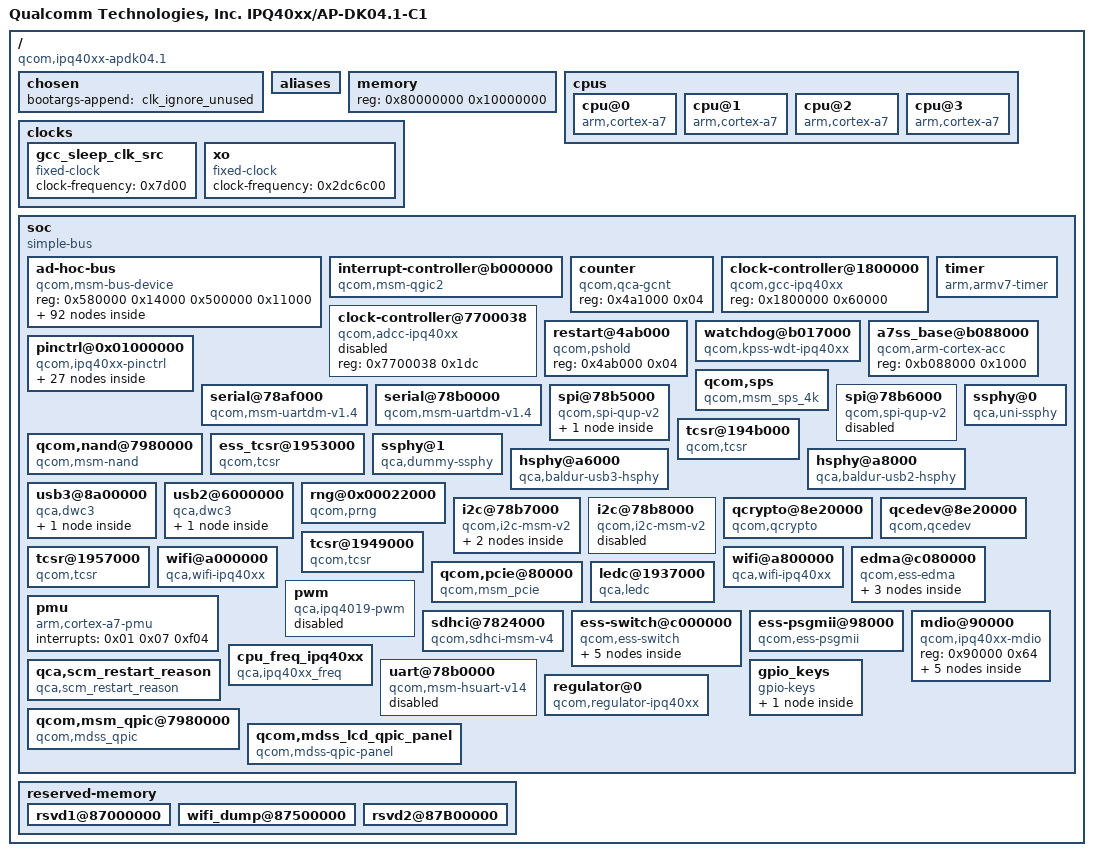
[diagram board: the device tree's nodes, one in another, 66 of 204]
/dts-v1/;

/ {
	#address-cells = <0x01>;
	#size-cells = <0x01>;
	model = "Qualcomm Technologies, Inc. IPQ40xx/AP-DK04.1-C1";
	compatible = "qcom,ipq40xx-apdk04.1\0qcom,ipq40xx";
	interrupt-parent = <0x01>;

	chosen {
		bootargs-append = " clk_ignore_unused";
	};

	aliases {
		spi0 = "/soc/spi@78b5000";
		spi1 = "/soc/spi@78b6000";
		i2c0 = "/soc/i2c@78b7000";
		i2c1 = "/soc/i2c@78b8000";
		ethernet0 = "/soc/edma/gmac0";
		ethernet1 = "/soc/edma/gmac1";
		ethernet2 = "/soc/edma/gmac2";
	};

	memory {
		device_type = "memory";
		reg = <0x80000000 0x10000000>;
	};

	cpus {
		#address-cells = <0x01>;
		#size-cells = <0x00>;

		cpu@0 {
			device_type = "cpu";
			compatible = "arm,cortex-a7";
			enable-method = "qcom,arm-cortex-acc";
			reg = <0x00>;
			clocks = <0x02 0x09>;
			clock-frequency = <0x00>;
		};

		cpu@1 {
			device_type = "cpu";
			compatible = "arm,cortex-a7";
			enable-method = "qcom,arm-cortex-acc";
			reg = <0x01>;
			clocks = <0x02 0x09>;
			clock-frequency = <0x00>;
		};

		cpu@2 {
			device_type = "cpu";
			compatible = "arm,cortex-a7";
			enable-method = "qcom,arm-cortex-acc";
			reg = <0x02>;
			clocks = <0x02 0x09>;
			clock-frequency = <0x00>;
		};

		cpu@3 {
			device_type = "cpu";
			compatible = "arm,cortex-a7";
			enable-method = "qcom,arm-cortex-acc";
			reg = <0x03>;
			clocks = <0x02 0x09>;
			clock-frequency = <0x00>;
		};
	};

	clocks {

		gcc_sleep_clk_src {
			compatible = "fixed-clock";
			clock-frequency = <0x7d00>;
			#clock-cells = <0x00>;
			linux,phandle = <0x47>;
			phandle = <0x47>;
		};

		xo {
			compatible = "fixed-clock";
			clock-frequency = <0x2dc6c00>;
			#clock-cells = <0x00>;
		};
	};

	soc {
		#address-cells = <0x01>;
		#size-cells = <0x01>;
		ranges;
		compatible = "simple-bus";

		ad-hoc-bus {
			compatible = "qcom,msm-bus-device";
			reg = <0x580000 0x14000 0x500000 0x11000>;
			reg-names = "snoc-base\0pcnoc-base";

			fab-pcnoc {
				cell-id = <0x1000>;
				label = "fab-pcnoc";
				qcom,fab-dev;
				qcom,base-name = "pcnoc-base";
				qcom,bypass-qos-prg;
				qcom,bus-type = <0x01>;
				qcom,qos-off = <0x1000>;
				qcom,base-offset = <0x00>;
				clocks;
				linux,phandle = <0x04>;
				phandle = <0x04>;
			};

			fab-snoc {
				cell-id = <0x400>;
				label = "fab-snoc";
				qcom,fab-dev;
				qcom,base-name = "snoc-base";
				qcom,bypass-qos-prg;
				qcom,bus-type = <0x01>;
				qcom,qos-off = <0x80>;
				qcom,base-offset = <0x00>;
				clocks;
				linux,phandle = <0x31>;
				phandle = <0x31>;
			};

			mas-blsp-bam {
				cell-id = <0x6d>;
				label = "mas-blsp-bam";
				qcom,buswidth = <0x04>;
				qcom,ap-owned;
				qcom,connections = <0x03>;
				qcom,bus-dev = <0x04>;
				qcom,mas-rpm-id = <0x82>;
				qcom,blacklist = <0x05 0x06 0x07 0x08 0x09 0x0a 0x0b 0x0c 0x0d 0x0e 0x0f 0x10 0x11 0x12 0x13 0x14 0x15 0x16 0x17 0x18 0x19 0x1a 0x1b 0x1c 0x1d 0x1e 0x1f 0x20 0x21 0x22 0x23 0x24 0x25 0x26 0x27 0x28 0x29 0x2a>;
			};

			mas-usb2-bam {
				cell-id = <0x6e>;
				label = "mas-usb2-bam";
				qcom,buswidth = <0x08>;
				qcom,ap-owned;
				qcom,qport = <0x0f>;
				qcom,qos-mode = "fixed";
				qcom,connections = <0x2b>;
				qcom,prio1 = <0x01>;
				qcom,prio0 = <0x01>;
				qcom,bus-dev = <0x04>;
				qcom,mas-rpm-id = <0x83>;
				qcom,blacklist = <0x05 0x06 0x07 0x08 0x09 0x0a 0x0b 0x0c 0x0d 0x0e 0x0f 0x10 0x11 0x12 0x13 0x14 0x15 0x16 0x17 0x18 0x19 0x1a 0x1b 0x1c 0x1d 0x1e 0x1f 0x20 0x21 0x22 0x23 0x24 0x25 0x26 0x27 0x28 0x29 0x2a>;
			};

			mas-adss-dma0 {
				cell-id = <0x6f>;
				label = "mas-adss-dma0";
				qcom,buswidth = <0x04>;
				qcom,ap-owned;
				qcom,connections = <0x2c>;
				qcom,bus-dev = <0x04>;
				qcom,mas-rpm-id = <0x84>;
				qcom,blacklist = <0x05 0x06 0x07 0x08 0x09 0x0a 0x0b 0x0c 0x0d 0x0e 0x0f 0x10 0x11 0x12 0x13 0x14 0x15 0x16 0x17 0x18 0x19 0x1a 0x1b 0x1c 0x1d 0x1e 0x1f 0x20 0x21 0x22 0x23 0x24 0x25 0x26 0x27 0x28 0x29 0x2a>;
			};

			mas-adss-dma1 {
				cell-id = <0x70>;
				label = "mas-adss-dma1";
				qcom,buswidth = <0x04>;
				qcom,ap-owned;
				qcom,connections = <0x2c>;
				qcom,bus-dev = <0x04>;
				qcom,mas-rpm-id = <0x85>;
				qcom,blacklist = <0x05 0x06 0x07 0x08 0x09 0x0a 0x0b 0x0c 0x0d 0x0e 0x0f 0x10 0x11 0x12 0x13 0x14 0x15 0x16 0x17 0x18 0x19 0x1a 0x1b 0x1c 0x1d 0x1e 0x1f 0x20 0x21 0x22 0x23 0x24 0x25 0x26 0x27 0x28 0x29 0x2a>;
			};

			mas-adss-dma2 {
				cell-id = <0x71>;
				label = "mas-adss-dma2";
				qcom,buswidth = <0x04>;
				qcom,ap-owned;
				qcom,connections = <0x2c>;
				qcom,bus-dev = <0x04>;
				qcom,mas-rpm-id = <0x86>;
				qcom,blacklist = <0x05 0x06 0x07 0x08 0x09 0x0a 0x0b 0x0c 0x0d 0x0e 0x0f 0x10 0x11 0x12 0x13 0x14 0x15 0x16 0x17 0x18 0x19 0x1a 0x1b 0x1c 0x1d 0x1e 0x1f 0x20 0x21 0x22 0x23 0x24 0x25 0x26 0x27 0x28 0x29 0x2a>;
			};

			mas-adss-dma3 {
				cell-id = <0x72>;
				label = "mas-adss-dma3";
				qcom,buswidth = <0x04>;
				qcom,ap-owned;
				qcom,connections = <0x2c>;
				qcom,bus-dev = <0x04>;
				qcom,mas-rpm-id = <0x87>;
				qcom,blacklist = <0x05 0x06 0x07 0x08 0x09 0x0a 0x0b 0x0c 0x0d 0x0e 0x0f 0x10 0x11 0x12 0x13 0x14 0x15 0x16 0x17 0x18 0x19 0x1a 0x1b 0x1c 0x1d 0x1e 0x1f 0x20 0x21 0x22 0x23 0x24 0x25 0x26 0x27 0x28 0x29 0x2a>;
			};

			mas-qpic-bam {
				cell-id = <0x73>;
				label = "mas-qpic-bam";
				qcom,buswidth = <0x04>;
				qcom,ap-owned;
				qcom,connections = <0x03>;
				qcom,bus-dev = <0x04>;
				qcom,mas-rpm-id = <0x88>;
				qcom,blacklist = <0x05 0x06 0x07 0x08 0x09 0x0a 0x0b 0x0c 0x0d 0x0e 0x0f 0x10 0x11 0x12 0x13 0x14 0x15 0x16 0x17 0x18 0x19 0x1a 0x1b 0x1c 0x1d 0x1e 0x1f 0x20 0x21 0x22 0x23 0x24 0x25 0x26 0x27 0x28 0x29 0x2a>;
			};

			mas-spdm {
				cell-id = <0x24>;
				label = "mas-spdm";
				qcom,buswidth = <0x04>;
				qcom,ap-owned;
				qcom,connections = <0x03>;
				qcom,bus-dev = <0x04>;
				qcom,mas-rpm-id = <0x32>;
				qcom,blacklist = <0x05 0x06 0x07 0x08 0x09 0x0a 0x0b 0x0c 0x0d 0x0e 0x0f 0x10 0x11 0x12 0x13 0x14 0x15 0x16 0x17 0x18 0x19 0x1a 0x1b 0x1c 0x1d 0x1e 0x1f 0x20 0x21 0x22 0x23 0x24 0x25 0x26 0x27 0x28 0x29 0x2a>;
			};

			mas-pcnoc-cfg {
				cell-id = <0x58>;
				label = "mas-pcnoc-cfg";
				qcom,buswidth = <0x04>;
				qcom,ap-owned;
				qcom,connections = <0x26>;
				qcom,bus-dev = <0x04>;
				qcom,mas-rpm-id = <0x54>;
			};

			mas-tic {
				cell-id = <0x4d>;
				label = "mas-tic";
				qcom,buswidth = <0x04>;
				qcom,ap-owned;
				qcom,connections = <0x2d 0x2b>;
				qcom,bus-dev = <0x04>;
				qcom,mas-rpm-id = <0x33>;
			};

			mas-sdcc-bam {
				cell-id = <0x74>;
				label = "mas-sdcc-bam";
				qcom,buswidth = <0x08>;
				qcom,ap-owned;
				qcom,qport = <0x0e>;
				qcom,qos-mode = "fixed";
				qcom,connections = <0x2b>;
				qcom,prio1 = <0x00>;
				qcom,prio0 = <0x00>;
				qcom,bus-dev = <0x04>;
				qcom,mas-rpm-id = <0x89>;
				qcom,blacklist = <0x05 0x06 0x07 0x08 0x09 0x0a 0x0b 0x0c 0x0d 0x0e 0x0f 0x10 0x11 0x12 0x13 0x14 0x15 0x16 0x17 0x18 0x19 0x1a 0x1b 0x1c 0x1d 0x1e 0x1f 0x20 0x21 0x22 0x23 0x24 0x25 0x26 0x27 0x28 0x29 0x2a>;
			};

			mas-snoc-pcnoc {
				cell-id = <0x2739>;
				label = "mas-snoc-pcnoc";
				qcom,buswidth = <0x04>;
				qcom,ap-owned;
				qcom,qport = <0x10>;
				qcom,qos-mode = "fixed";
				qcom,connections = <0x2d>;
				qcom,prio1 = <0x00>;
				qcom,prio0 = <0x00>;
				qcom,bus-dev = <0x04>;
				qcom,mas-rpm-id = <0x4d>;
			};

			mas-qdss-dap {
				cell-id = <0x4c>;
				label = "mas-qdss-dap";
				qcom,buswidth = <0x04>;
				qcom,ap-owned;
				qcom,connections = <0x2d 0x2b>;
				qcom,bus-dev = <0x04>;
				qcom,mas-rpm-id = <0x31>;
			};

			mas-ddrc-snoc {
				cell-id = <0x75>;
				label = "mas-ddrc-snoc";
				qcom,buswidth = <0x10>;
				qcom,ap-owned;
				qcom,connections = <0x2e 0x2f 0x30>;
				qcom,bus-dev = <0x31>;
				qcom,mas-rpm-id = <0x8a>;
				qcom,blacklist = <0x32 0x33>;
			};

			mas-wss-0 {
				cell-id = <0x76>;
				label = "mas-wss-0";
				qcom,buswidth = <0x04>;
				qcom,ap-owned;
				qcom,qport = <0x1a>;
				qcom,qos-mode = "fixed";
				qcom,connections = <0x2e 0x32>;
				qcom,prio1 = <0x00>;
				qcom,prio0 = <0x00>;
				qcom,bus-dev = <0x31>;
				qcom,mas-rpm-id = <0x8b>;
				qcom,blacklist = <0x34 0x35 0x30 0x36 0x37 0x38 0x33>;
			};

			mas-wss-1 {
				cell-id = <0x77>;
				label = "mas-wss-1";
				qcom,buswidth = <0x04>;
				qcom,ap-owned;
				qcom,qport = <0x1b>;
				qcom,qos-mode = "fixed";
				qcom,connections = <0x2e 0x32>;
				qcom,prio1 = <0x00>;
				qcom,prio0 = <0x00>;
				qcom,bus-dev = <0x31>;
				qcom,mas-rpm-id = <0x8c>;
				qcom,blacklist = <0x34 0x35 0x30 0x36 0x37 0x38 0x33>;
			};

			mas-crypto {
				cell-id = <0x2f>;
				label = "mas-crypto";
				qcom,buswidth = <0x08>;
				qcom,ap-owned;
				qcom,qport = <0x05>;
				qcom,qos-mode = "fixed";
				qcom,connections = <0x2e 0x2f 0x32>;
				qcom,prio1 = <0x00>;
				qcom,prio0 = <0x00>;
				qcom,bus-dev = <0x31>;
				qcom,mas-rpm-id = <0x17>;
				qcom,blacklist = <0x34 0x35 0x39 0x30 0x3a 0x38 0x33>;
			};

			mas-ess {
				cell-id = <0x78>;
				label = "mas-ess";
				qcom,buswidth = <0x08>;
				qcom,ap-owned;
				qcom,qport = <0x2c>;
				qcom,qos-mode = "fixed";
				qcom,connections = <0x2e 0x32>;
				qcom,prio1 = <0x00>;
				qcom,prio0 = <0x00>;
				qcom,bus-dev = <0x31>;
				qcom,mas-rpm-id = <0x8d>;
				qcom,blacklist = <0x34 0x35 0x39 0x30 0x3a 0x36 0x37 0x38 0x33>;
			};

			mas-pcie {
				cell-id = <0x2d>;
				label = "mas-pcie";
				qcom,buswidth = <0x08>;
				qcom,ap-owned;
				qcom,qport = <0x06>;
				qcom,qos-mode = "fixed";
				qcom,connections = <0x2e 0x32>;
				qcom,prio1 = <0x00>;
				qcom,prio0 = <0x00>;
				qcom,bus-dev = <0x31>;
				qcom,mas-rpm-id = <0x8e>;
				qcom,blacklist = <0x34 0x35 0x30 0x3a 0x36 0x37 0x38 0x33>;
			};

			mas-usb3 {
				cell-id = <0x3d>;
				label = "mas-usb3";
				qcom,buswidth = <0x08>;
				qcom,ap-owned;
				qcom,qport = <0x07>;
				qcom,qos-mode = "fixed";
				qcom,connections = <0x2e 0x32>;
				qcom,prio1 = <0x00>;
				qcom,prio0 = <0x00>;
				qcom,bus-dev = <0x31>;
				qcom,mas-rpm-id = <0x20>;
				qcom,blacklist = <0x34 0x35 0x39 0x30 0x3a 0x36 0x37 0x38 0x33>;
			};

			mas-qdss-etr {
				cell-id = <0x3c>;
				label = "mas-qdss-etr";
				qcom,buswidth = <0x08>;
				qcom,ap-owned;
				qcom,qport = <0x220>;
				qcom,qos-mode = "fixed";
				qcom,connections = <0x3b>;
				qcom,prio1 = <0x00>;
				qcom,prio0 = <0x00>;
				qcom,bus-dev = <0x31>;
				qcom,mas-rpm-id = <0x1f>;
				qcom,blacklist = <0x34 0x35 0x39 0x30 0x3a 0x36 0x37 0x38 0x33>;
			};

			mas-qdss-bamndp {
				cell-id = <0x79>;
				label = "mas-qdss-bamndp";
				qcom,buswidth = <0x04>;
				qcom,ap-owned;
				qcom,qport = <0x240>;
				qcom,qos-mode = "fixed";
				qcom,connections = <0x3b>;
				qcom,prio1 = <0x00>;
				qcom,prio0 = <0x00>;
				qcom,bus-dev = <0x31>;
				qcom,mas-rpm-id = <0x8f>;
				qcom,blacklist = <0x34 0x35 0x39 0x30 0x3a 0x36 0x37 0x38 0x33>;
			};

			mas-pcnoc-snoc {
				cell-id = <0x271a>;
				label = "mas-pcnoc-snoc";
				qcom,buswidth = <0x04>;
				qcom,ap-owned;
				qcom,qport = <0x180>;
				qcom,qos-mode = "fixed";
				qcom,connections = <0x2e 0x2f 0x32>;
				qcom,prio1 = <0x00>;
				qcom,prio0 = <0x00>;
				qcom,bus-dev = <0x31>;
				qcom,mas-rpm-id = <0x1d>;
				qcom,blacklist = <0x33>;
			};

			mas-snoc-cfg {
				cell-id = <0x7a>;
				label = "mas-snoc-cfg";
				qcom,buswidth = <0x04>;
				qcom,ap-owned;
				qcom,connections = <0x33>;
				qcom,bus-dev = <0x31>;
				qcom,mas-rpm-id = <0x90>;
			};

			pcnoc-m-0 {
				cell-id = <0x271e>;
				label = "pcnoc-m-0";
				qcom,buswidth = <0x04>;
				qcom,ap-owned;
				qcom,qport = <0x0c>;
				qcom,qos-mode = "fixed";
				qcom,connections = <0x2b>;
				qcom,prio1 = <0x01>;
				qcom,prio0 = <0x01>;
				qcom,bus-dev = <0x04>;
				qcom,mas-rpm-id = <0x57>;
				qcom,slv-rpm-id = <0x74>;
				linux,phandle = <0x03>;
				phandle = <0x03>;
			};

			pcnoc-m-1 {
				cell-id = <0x271f>;
				label = "pcnoc-m-1";
				qcom,buswidth = <0x04>;
				qcom,ap-owned;
				qcom,qport = <0x0d>;
				qcom,qos-mode = "fixed";
				qcom,connections = <0x2b>;
				qcom,prio1 = <0x01>;
				qcom,prio0 = <0x01>;
				qcom,bus-dev = <0x04>;
				qcom,mas-rpm-id = <0x58>;
				qcom,slv-rpm-id = <0x75>;
				linux,phandle = <0x2c>;
				phandle = <0x2c>;
			};

			pcnoc-int-0 {
				cell-id = <0x271c>;
				label = "pcnoc-int-0";
				qcom,buswidth = <0x08>;
				qcom,ap-owned;
				qcom,connections = <0x3c 0x3d 0x3e 0x3f 0x40 0x41 0x42 0x43 0x44 0x45>;
				qcom,bus-dev = <0x04>;
				qcom,mas-rpm-id = <0x55>;
				qcom,slv-rpm-id = <0x72>;
				linux,phandle = <0x2d>;
				phandle = <0x2d>;
			};

			pcnoc-s-0 {
				cell-id = <0x2722>;
				label = "pcnoc-s-0";
				qcom,buswidth = <0x04>;
				qcom,ap-owned;
				qcom,connections = <0x22 0x05 0x1b 0x17>;
				qcom,bus-dev = <0x04>;
				qcom,mas-rpm-id = <0x59>;
				qcom,slv-rpm-id = <0x76>;
				linux,phandle = <0x3e>;
				phandle = <0x3e>;
			};

			pcnoc-s-1 {
				cell-id = <0x2723>;
				label = "pcnoc-s-1";
				qcom,buswidth = <0x04>;
				qcom,ap-owned;
				qcom,connections = <0x19 0x12 0x10>;
				qcom,bus-dev = <0x04>;
				qcom,mas-rpm-id = <0x5a>;
				qcom,slv-rpm-id = <0x77>;
				linux,phandle = <0x3c>;
				phandle = <0x3c>;
			};

			pcnoc-s-2 {
				cell-id = <0x2724>;
				label = "pcnoc-s-2";
				qcom,buswidth = <0x04>;
				qcom,ap-owned;
				qcom,connections = <0x1c 0x1d 0x0e 0x1a>;
				qcom,bus-dev = <0x04>;
				qcom,mas-rpm-id = <0x5b>;
				qcom,slv-rpm-id = <0x78>;
				linux,phandle = <0x3d>;
				phandle = <0x3d>;
			};

			pcnoc-s-3 {
				cell-id = <0x2725>;
				label = "pcnoc-s-3";
				qcom,buswidth = <0x04>;
				qcom,ap-owned;
				qcom,connections = <0x13 0x16 0x2a 0x27>;
				qcom,bus-dev = <0x04>;
				qcom,mas-rpm-id = <0x5c>;
				qcom,slv-rpm-id = <0x79>;
				linux,phandle = <0x45>;
				phandle = <0x45>;
			};

			pcnoc-s-4 {
				cell-id = <0x2726>;
				label = "pcnoc-s-4";
				qcom,buswidth = <0x04>;
				qcom,ap-owned;
				qcom,connections = <0x07 0x21 0x23>;
				qcom,bus-dev = <0x04>;
				qcom,mas-rpm-id = <0x5d>;
				qcom,slv-rpm-id = <0x7a>;
				linux,phandle = <0x3f>;
				phandle = <0x3f>;
			};

			pcnoc-s-5 {
				cell-id = <0x273f>;
				label = "pcnoc-s-5";
				qcom,buswidth = <0x04>;
				qcom,ap-owned;
				qcom,connections = <0x20 0x08 0x06 0x11>;
				qcom,bus-dev = <0x04>;
				qcom,mas-rpm-id = <0x81>;
				qcom,slv-rpm-id = <0xbd>;
				linux,phandle = <0x40>;
				phandle = <0x40>;
			};

			pcnoc-s-6 {
				cell-id = <0x2740>;
				label = "pcnoc-s-6";
				qcom,buswidth = <0x04>;
				qcom,ap-owned;
				qcom,connections = <0x0b 0x15 0x1e 0x0d 0x0a>;
				qcom,bus-dev = <0x04>;
				qcom,mas-rpm-id = <0x5e>;
				qcom,slv-rpm-id = <0x7b>;
				linux,phandle = <0x41>;
				phandle = <0x41>;
			};

			pcnoc-s-7 {
				cell-id = <0x2752>;
				label = "pcnoc-s-7";
				qcom,buswidth = <0x04>;
				qcom,ap-owned;
				qcom,connections = <0x0f 0x25 0x1f>;
				qcom,bus-dev = <0x04>;
				qcom,mas-rpm-id = <0x5f>;
				qcom,slv-rpm-id = <0x7c>;
				linux,phandle = <0x42>;
				phandle = <0x42>;
			};

			pcnoc-s-8 {
				cell-id = <0x2727>;
				label = "pcnoc-s-8";
				qcom,buswidth = <0x04>;
				qcom,ap-owned;
				qcom,connections = <0x29 0x0c 0x24>;
				qcom,bus-dev = <0x04>;
				qcom,mas-rpm-id = <0x60>;
				qcom,slv-rpm-id = <0x7d>;
				linux,phandle = <0x43>;
				phandle = <0x43>;
			};

			pcnoc-s-9 {
				cell-id = <0x2728>;
				label = "pcnoc-s-9";
				qcom,buswidth = <0x04>;
				qcom,ap-owned;
				qcom,connections = <0x09 0x28 0x18 0x14>;
				qcom,bus-dev = <0x04>;
				qcom,mas-rpm-id = <0x61>;
				qcom,slv-rpm-id = <0x7e>;
				linux,phandle = <0x44>;
				phandle = <0x44>;
			};

			snoc-int-0 {
				cell-id = <0x2714>;
				label = "snoc-int-0";
				qcom,buswidth = <0x08>;
				qcom,ap-owned;
				qcom,connections = <0x46 0x3a>;
				qcom,bus-dev = <0x31>;
				qcom,mas-rpm-id = <0x63>;
				qcom,slv-rpm-id = <0x82>;
				linux,phandle = <0x2e>;
				phandle = <0x2e>;
			};

			snoc-int-1 {
				cell-id = <0x2715>;
				label = "snoc-int-1";
				qcom,buswidth = <0x08>;
				qcom,ap-owned;
				qcom,connections = <0x38 0x39 0x35 0x34 0x36 0x37>;
				qcom,bus-dev = <0x31>;
				qcom,mas-rpm-id = <0x64>;
				qcom,slv-rpm-id = <0x83>;
				linux,phandle = <0x2f>;
				phandle = <0x2f>;
			};

			qdss-int {
				cell-id = <0x2719>;
				label = "qdss-int";
				qcom,buswidth = <0x08>;
				qcom,ap-owned;
				qcom,connections = <0x2e 0x32>;
				qcom,bus-dev = <0x31>;
				qcom,mas-rpm-id = <0x62>;
				qcom,slv-rpm-id = <0x80>;
				linux,phandle = <0x3b>;
				phandle = <0x3b>;
			};

			slv-clk-ctl {
				cell-id = <0x26c>;
				label = "slv-clk-ctl";
				qcom,buswidth = <0x04>;
				qcom,ap-owned;
				qcom,bus-dev = <0x04>;
				qcom,slv-rpm-id = <0x2f>;
				linux,phandle = <0x22>;
				phandle = <0x22>;
			};

			slv-security {
				cell-id = <0x26e>;
				label = "slv-security";
				qcom,buswidth = <0x04>;
				qcom,ap-owned;
				qcom,bus-dev = <0x04>;
				qcom,slv-rpm-id = <0x31>;
				linux,phandle = <0x1b>;
				phandle = <0x1b>;
			};

			slv-tcsr {
				cell-id = <0x26f>;
				label = "slv-tcsr";
				qcom,buswidth = <0x04>;
				qcom,ap-owned;
				qcom,bus-dev = <0x04>;
				qcom,slv-rpm-id = <0x32>;
				linux,phandle = <0x05>;
				phandle = <0x05>;
			};

			slv-tlmm {
				cell-id = <0x270>;
				label = "slv-tlmm";
				qcom,buswidth = <0x04>;
				qcom,ap-owned;
				qcom,bus-dev = <0x04>;
				qcom,slv-rpm-id = <0x33>;
				linux,phandle = <0x17>;
				phandle = <0x17>;
			};

			slv-imem-cfg {
				cell-id = <0x273>;
				label = "slv-imem-cfg";
				qcom,buswidth = <0x04>;
				qcom,ap-owned;
				qcom,bus-dev = <0x04>;
				qcom,slv-rpm-id = <0x36>;
				linux,phandle = <0x10>;
				phandle = <0x10>;
			};

			slv-prng {
				cell-id = <0x26a>;
				label = "slv-prng";
				qcom,buswidth = <0x04>;
				qcom,ap-owned;
				qcom,bus-dev = <0x04>;
				qcom,slv-rpm-id = <0x2c>;
				linux,phandle = <0x12>;
				phandle = <0x12>;
			};

			slv-prng-apu-cfg {
				cell-id = <0x2cc>;
				label = "slv-prng-apu-cfg";
				qcom,buswidth = <0x04>;
				qcom,ap-owned;
				qcom,bus-dev = <0x04>;
				qcom,slv-rpm-id = <0xbe>;
				linux,phandle = <0x19>;
				phandle = <0x19>;
			};

			slv-boot-rom {
				cell-id = <0x276>;
				label = "slv-boot-rom";
				qcom,buswidth = <0x04>;
				qcom,ap-owned;
				qcom,bus-dev = <0x04>;
				qcom,slv-rpm-id = <0x39>;
				linux,phandle = <0x1a>;
				phandle = <0x1a>;
			};

			slv-spdm {
				cell-id = <0x279>;
				label = "slv-spdm";
				qcom,buswidth = <0x04>;
				qcom,ap-owned;
				qcom,bus-dev = <0x04>;
				qcom,slv-rpm-id = <0x3c>;
				linux,phandle = <0x1c>;
				phandle = <0x1c>;
			};

			slv-pcnoc-cfg {
				cell-id = <0x281>;
				label = "slv-pcnoc-cfg";
				qcom,buswidth = <0x04>;
				qcom,ap-owned;
				qcom,bus-dev = <0x04>;
				qcom,slv-rpm-id = <0x45>;
				linux,phandle = <0x0e>;
				phandle = <0x0e>;
			};

			slv-pcnoc-mpu-cfg {
				cell-id = <0x2cd>;
				label = "slv-pcnoc-mpu-cfg";
				qcom,buswidth = <0x04>;
				qcom,ap-owned;
				qcom,bus-dev = <0x04>;
				qcom,slv-rpm-id = <0xbf>;
				linux,phandle = <0x1d>;
				phandle = <0x1d>;
			};

			slv-gcnt {
				cell-id = <0x2ce>;
				label = "slv-gcnt";
				qcom,buswidth = <0x04>;
				qcom,ap-owned;
				qcom,bus-dev = <0x04>;
				qcom,slv-rpm-id = <0xc0>;
				linux,phandle = <0x16>;
				phandle = <0x16>;
			};

			slv-qdss-cfg {
				cell-id = <0x27b>;
				label = "slv-qdss-cfg";
				qcom,buswidth = <0x04>;
				qcom,ap-owned;
				qcom,bus-dev = <0x04>;
				qcom,slv-rpm-id = <0x3f>;
				linux,phandle = <0x13>;
				phandle = <0x13>;
			};

			slv-snoc-cfg {
				cell-id = <0x282>;
				label = "slv-snoc-cfg";
				qcom,buswidth = <0x04>;
				qcom,ap-owned;
				qcom,bus-dev = <0x04>;
				qcom,slv-rpm-id = <0x46>;
				linux,phandle = <0x2a>;
				phandle = <0x2a>;
			};

			slv-snoc-mpu-cfg {
				cell-id = <0x27e>;
				label = "slv-snoc-mpu-cfg";
				qcom,buswidth = <0x04>;
				qcom,ap-owned;
				qcom,bus-dev = <0x04>;
				qcom,slv-rpm-id = <0x43>;
				linux,phandle = <0x27>;
				phandle = <0x27>;
			};

			slv-adss-cfg {
				cell-id = <0x2cf>;
				label = "slv-adss-cfg";
				qcom,buswidth = <0x04>;
				qcom,ap-owned;
				qcom,bus-dev = <0x04>;
				qcom,slv-rpm-id = <0xc1>;
				linux,phandle = <0x07>;
				phandle = <0x07>;
			};

			slv-adss-apu {
				cell-id = <0x2d0>;
				label = "slv-adss-apu";
				qcom,buswidth = <0x04>;
				qcom,ap-owned;
				qcom,bus-dev = <0x04>;
				qcom,slv-rpm-id = <0xc2>;
				linux,phandle = <0x23>;
				phandle = <0x23>;
			};

			slv-adss-vmidmt-cfg {
				cell-id = <0x2d0>;
				label = "slv-adss-vmidmt-cfg";
				qcom,buswidth = <0x04>;
				qcom,ap-owned;
				qcom,bus-dev = <0x04>;
				qcom,slv-rpm-id = <0xc3>;
				linux,phandle = <0x21>;
				phandle = <0x21>;
			};

			slv-qhss-apu-cfg {
				cell-id = <0x2d1>;
				label = "slv-qhss-apu-cfg";
				qcom,buswidth = <0x04>;
				qcom,ap-owned;
				qcom,bus-dev = <0x04>;
				qcom,slv-rpm-id = <0xc4>;
				linux,phandle = <0x20>;
				phandle = <0x20>;
			};

			slv-mdio {
				cell-id = <0x2d2>;
				label = "slv-mdio";
				qcom,buswidth = <0x04>;
				qcom,ap-owned;
				qcom,bus-dev = <0x04>;
				qcom,slv-rpm-id = <0xc5>;
				linux,phandle = <0x06>;
				phandle = <0x06>;
			};

			slv-fephy-cfg {
				cell-id = <0x2d3>;
				label = "slv-fephy-cfg";
				qcom,buswidth = <0x04>;
				qcom,ap-owned;
				qcom,bus-dev = <0x04>;
				qcom,slv-rpm-id = <0xc6>;
				linux,phandle = <0x08>;
				phandle = <0x08>;
			};

			slv-srif {
				cell-id = <0x2d4>;
				label = "slv-srif";
				qcom,buswidth = <0x04>;
				qcom,ap-owned;
				qcom,bus-dev = <0x04>;
				qcom,slv-rpm-id = <0xc7>;
				linux,phandle = <0x11>;
				phandle = <0x11>;
			};

			slv-ddrc-cfg {
				cell-id = <0x2db>;
				label = "slv-ddrc-cfg";
				qcom,buswidth = <0x04>;
				qcom,ap-owned;
				qcom,bus-dev = <0x04>;
				qcom,slv-rpm-id = <0xc8>;
				linux,phandle = <0x0d>;
				phandle = <0x0d>;
			};

			slv-ddrc-apu-cfg {
				cell-id = <0x2dc>;
				label = "slv-ddrc-apu-cfg";
				qcom,buswidth = <0x04>;
				qcom,ap-owned;
				qcom,bus-dev = <0x04>;
				qcom,slv-rpm-id = <0xc9>;
				linux,phandle = <0x15>;
				phandle = <0x15>;
			};

			slv-ddrc-mpu0-cfg {
				cell-id = <0x2dd>;
				label = "slv-ddrc-mpu0-cfg";
				qcom,buswidth = <0x04>;
				qcom,ap-owned;
				qcom,bus-dev = <0x04>;
				qcom,slv-rpm-id = <0xca>;
				linux,phandle = <0x0b>;
				phandle = <0x0b>;
			};

			slv-ddrc-mpu1-cfg {
				cell-id = <0x2de>;
				label = "slv-ddrc-mpu1-cfg";
				qcom,buswidth = <0x04>;
				qcom,ap-owned;
				qcom,bus-dev = <0x04>;
				qcom,slv-rpm-id = <0xcb>;
				linux,phandle = <0x0a>;
				phandle = <0x0a>;
			};

			slv-ddrc-mpu2-cfg {
				cell-id = <0x2de>;
				label = "slv-ddrc-mpu2-cfg";
				qcom,buswidth = <0x04>;
				qcom,ap-owned;
				qcom,bus-dev = <0x04>;
				qcom,slv-rpm-id = <0xd2>;
				linux,phandle = <0x1e>;
				phandle = <0x1e>;
			};

			slv-ess-vmidmt-cfg {
				cell-id = <0x2df>;
				label = "slv-ess-vmidmt-cfg";
				qcom,buswidth = <0x04>;
				qcom,ap-owned;
				qcom,bus-dev = <0x04>;
				qcom,slv-rpm-id = <0xd3>;
				linux,phandle = <0x1f>;
				phandle = <0x1f>;
			};

			slv-ess-apu-cfg {
				cell-id = <0x2e0>;
				label = "slv-ess-apu-cfg";
				qcom,buswidth = <0x04>;
				qcom,ap-owned;
				qcom,bus-dev = <0x04>;
				qcom,slv-rpm-id = <0xd4>;
				linux,phandle = <0x0f>;
				phandle = <0x0f>;
			};

			slv-usb2-cfg {
				cell-id = <0x2e1>;
				label = "slv-usb2-cfg";
				qcom,buswidth = <0x04>;
				qcom,ap-owned;
				qcom,bus-dev = <0x04>;
				qcom,slv-rpm-id = <0xd5>;
				linux,phandle = <0x25>;
				phandle = <0x25>;
			};

			slv-blsp-cfg {
				cell-id = <0x2e2>;
				label = "slv-blsp-cfg";
				qcom,buswidth = <0x04>;
				qcom,ap-owned;
				qcom,bus-dev = <0x04>;
				qcom,slv-rpm-id = <0xd6>;
				linux,phandle = <0x24>;
				phandle = <0x24>;
			};

			slv-qpic-cfg {
				cell-id = <0x2e3>;
				label = "slv-qpic-cfg";
				qcom,buswidth = <0x04>;
				qcom,ap-owned;
				qcom,bus-dev = <0x04>;
				qcom,slv-rpm-id = <0xd7>;
				linux,phandle = <0x0c>;
				phandle = <0x0c>;
			};

			slv-sdcc-cfg {
				cell-id = <0x2e4>;
				label = "slv-sdcc-cfg";
				qcom,buswidth = <0x04>;
				qcom,ap-owned;
				qcom,bus-dev = <0x04>;
				qcom,slv-rpm-id = <0xd8>;
				linux,phandle = <0x29>;
				phandle = <0x29>;
			};

			slv-wss0-vmidmt-cfg {
				cell-id = <0x2e5>;
				label = "slv-wss0-vmidmt-cfg";
				qcom,buswidth = <0x04>;
				qcom,ap-owned;
				qcom,bus-dev = <0x04>;
				qcom,slv-rpm-id = <0xd9>;
				linux,phandle = <0x18>;
				phandle = <0x18>;
			};

			slv-wss0-apu-cfg {
				cell-id = <0x2e6>;
				label = "slv-wss0-apu-cfg";
				qcom,buswidth = <0x04>;
				qcom,ap-owned;
				qcom,bus-dev = <0x04>;
				qcom,slv-rpm-id = <0xda>;
				linux,phandle = <0x14>;
				phandle = <0x14>;
			};

			slv-wss1-vmidmt-cfg {
				cell-id = <0x2e7>;
				label = "slv-wss1-vmidmt-cfg";
				qcom,buswidth = <0x04>;
				qcom,ap-owned;
				qcom,bus-dev = <0x04>;
				qcom,slv-rpm-id = <0xdb>;
				linux,phandle = <0x28>;
				phandle = <0x28>;
			};

			slv-wss1-apu-cfg {
				cell-id = <0x2e8>;
				label = "slv-wss1-apu-cfg";
				qcom,buswidth = <0x04>;
				qcom,ap-owned;
				qcom,bus-dev = <0x04>;
				qcom,slv-rpm-id = <0xdc>;
				linux,phandle = <0x09>;
				phandle = <0x09>;
			};

			slv-pcnoc-snoc {
				cell-id = <0x271b>;
				label = "slv-pcnoc-snoc";
				qcom,buswidth = <0x04>;
				qcom,ap-owned;
				qcom,bus-dev = <0x04>;
				qcom,slv-rpm-id = <0x2d>;
				linux,phandle = <0x2b>;
				phandle = <0x2b>;
			};

			slv-srvc-pcnoc {
				cell-id = <0x2e9>;
				label = "slv-srvc-pcnoc";
				qcom,buswidth = <0x04>;
				qcom,ap-owned;
				qcom,bus-dev = <0x04>;
				qcom,slv-rpm-id = <0xdd>;
				linux,phandle = <0x26>;
				phandle = <0x26>;
			};

			slv-snoc-ddrc-m1 {
				cell-id = <0x2ea>;
				label = "slv-snoc-ddrc-m1";
				qcom,buswidth = <0x08>;
				qcom,ap-owned;
				qcom,bus-dev = <0x31>;
				qcom,slv-rpm-id = <0xde>;
				linux,phandle = <0x32>;
				phandle = <0x32>;
			};

			slv-a7ss {
				cell-id = <0x2eb>;
				label = "slv-a7ss";
				qcom,buswidth = <0x04>;
				qcom,ap-owned;
				qcom,bus-dev = <0x31>;
				qcom,slv-rpm-id = <0xdf>;
				linux,phandle = <0x39>;
				phandle = <0x39>;
			};

			slv-ocimem {
				cell-id = <0x249>;
				label = "slv-ocimem";
				qcom,buswidth = <0x08>;
				qcom,ap-owned;
				qcom,bus-dev = <0x31>;
				qcom,slv-rpm-id = <0x1a>;
				linux,phandle = <0x46>;
				phandle = <0x46>;
			};

			slv-wss0-cfg {
				cell-id = <0x2ec>;
				label = "slv-wss0-cfg";
				qcom,buswidth = <0x04>;
				qcom,ap-owned;
				qcom,bus-dev = <0x31>;
				qcom,slv-rpm-id = <0xe0>;
				linux,phandle = <0x37>;
				phandle = <0x37>;
			};

			slv-wss1-cfg {
				cell-id = <0x2ed>;
				label = "slv-wss1-cfg";
				qcom,buswidth = <0x04>;
				qcom,ap-owned;
				qcom,bus-dev = <0x31>;
				qcom,slv-rpm-id = <0xe1>;
				linux,phandle = <0x36>;
				phandle = <0x36>;
			};

			slv-pcie {
				cell-id = <0x2ee>;
				label = "slv-pcie";
				qcom,buswidth = <0x08>;
				qcom,ap-owned;
				qcom,bus-dev = <0x31>;
				qcom,slv-rpm-id = <0xe2>;
				linux,phandle = <0x30>;
				phandle = <0x30>;
			};

			slv-usb3-cfg {
				cell-id = <0x2ef>;
				label = "slv-usb3-cfg";
				qcom,buswidth = <0x04>;
				qcom,ap-owned;
				qcom,bus-dev = <0x31>;
				qcom,slv-rpm-id = <0xe3>;
				linux,phandle = <0x34>;
				phandle = <0x34>;
			};

			slv-crypto-cfg {
				cell-id = <0x2f0>;
				label = "slv-crypto-cfg";
				qcom,buswidth = <0x04>;
				qcom,ap-owned;
				qcom,bus-dev = <0x31>;
				qcom,slv-rpm-id = <0xe4>;
				linux,phandle = <0x38>;
				phandle = <0x38>;
			};

			slv-ess-cfg {
				cell-id = <0x2f1>;
				label = "slv-ess-cfg";
				qcom,buswidth = <0x04>;
				qcom,ap-owned;
				qcom,bus-dev = <0x31>;
				qcom,slv-rpm-id = <0xe5>;
				linux,phandle = <0x35>;
				phandle = <0x35>;
			};

			slv-qdss-stm {
				cell-id = <0x24c>;
				label = "slv-qdss-stm";
				qcom,buswidth = <0x04>;
				qcom,ap-owned;
				qcom,bus-dev = <0x31>;
				qcom,slv-rpm-id = <0x1e>;
				linux,phandle = <0x3a>;
				phandle = <0x3a>;
			};

			slv-srvc-snoc {
				cell-id = <0x2f2>;
				label = "slv-srvc-snoc";
				qcom,buswidth = <0x08>;
				qcom,ap-owned;
				qcom,bus-dev = <0x31>;
				qcom,slv-rpm-id = <0xe6>;
				linux,phandle = <0x33>;
				phandle = <0x33>;
			};
		};

		interrupt-controller@b000000 {
			compatible = "qcom,msm-qgic2";
			interrupt-controller;
			#interrupt-cells = <0x03>;
			reg = <0xb000000 0x1000 0xb002000 0x1000>;
			linux,phandle = <0x01>;
			phandle = <0x01>;
		};

		counter {
			compatible = "qcom,qca-gcnt";
			reg = <0x4a1000 0x04>;
		};

		clock-controller@1800000 {
			compatible = "qcom,gcc-ipq40xx";
			#clock-cells = <0x01>;
			#reset-cells = <0x01>;
			reg = <0x1800000 0x60000>;
			linux,phandle = <0x02>;
			phandle = <0x02>;
		};

		clock-controller@7700038 {
			compatible = "qcom,adcc-ipq40xx";
			#clock-cells = <0x01>;
			#reset-cells = <0x01>;
			reg = <0x7700038 0x1dc>;
			status = "disabled";
		};

		timer {
			compatible = "arm,armv7-timer";
			interrupts = <0x01 0x02 0xf08 0x01 0x03 0xf08 0x01 0x04 0xf08 0x01 0x01 0xf08>;
			clock-frequency = <0x2dc6c00>;
		};

		restart@4ab000 {
			compatible = "qcom,pshold";
			reg = <0x4ab000 0x04>;
		};

		watchdog@b017000 {
			compatible = "qcom,kpss-wdt-ipq40xx";
			reg = <0xb017000 0x40>;
			interrupt-names = "bark_irq";
			interrupts = <0x00 0x03 0x00>;
			clocks = <0x47>;
			timeout-sec = <0x0a>;
			wdt_res = <0x04>;
			wdt_en = <0x08>;
			wdt_bark_time = <0x10>;
			wdt_bite_time = <0x14>;
			status = "ok";
		};

		a7ss_base@b088000 {
			compatible = "qcom,arm-cortex-acc";
			reg = <0xb088000 0x1000>;
		};

		pinctrl@0x01000000 {
			compatible = "qcom,ipq40xx-pinctrl";
			reg = <0x1000000 0x300000>;
			gpio-controller;
			#gpio-cells = <0x02>;
			interrupt-controller;
			#interrupt-cells = <0x02>;
			interrupts = <0x00 0xd0 0x00>;
			linux,phandle = <0x51>;
			phandle = <0x51>;

			serial0_pinmux {
				linux,phandle = <0x48>;
				phandle = <0x48>;

				mux {
					pins = "gpio16\0gpio17";
					function = "blsp_uart0";
					bias-disable;
				};
			};

			led0_pinmux {
				linux,phandle = <0x52>;
				phandle = <0x52>;

				mux_1 {
					pins = "gpio36";
					function = "led0";
					bias-pull-down;
				};

				mux_2 {
					pins = "gpio40";
					function = "led4";
					bias-pull-down;
				};
			};

			serial1_pinmux {
				linux,phandle = <0x49>;
				phandle = <0x49>;

				mux {
					pins = "gpio8\0gpio9";
					function = "blsp_uart1";
					bias-disable;
				};
			};

			uart1_pinmux {
				linux,phandle = <0x56>;
				phandle = <0x56>;

				mux {
					pins = "gpio8\0gpio9\0gpio10\0gpio11";
					function = "blsp_uart1";
					bias-disable;
				};
			};

			spi_0_pinmux {
				linux,phandle = <0x4a>;
				phandle = <0x4a>;

				mux {
					pins = "gpio12\0gpio13\0gpio14\0gpio15";
					function = "blsp_spi0";
					bias-disable;
				};
			};

			i2c_0_pinmux {
				linux,phandle = <0x4f>;
				phandle = <0x4f>;

				mux {
					pins = "gpio20\0gpio21";
					function = "blsp_i2c0";
					bias-disable;
				};
			};

			sd_0_pinmux {
				linux,phandle = <0x53>;
				phandle = <0x53>;

				sd0 {
					pins = "gpio23";
					function = "sdio0";
					drive-strength = <0x0a>;
				};

				sd1 {
					pins = "gpio24";
					function = "sdio1";
					drive-strength = <0x0a>;
				};

				sd2 {
					pins = "gpio25";
					function = "sdio2";
					drive-strength = <0x0a>;
				};

				sd3 {
					pins = "gpio26";
					function = "sdio3";
					drive-strength = <0x0a>;
				};

				sdclk {
					pins = "gpio27";
					function = "sdio_clk";
					drive-strength = <0x10>;
				};

				sdcmd {
					pins = "gpio28";
					function = "sdio_cmd";
					drive-strength = <0x0a>;
				};

				sd4 {
					pins = "gpio29";
					function = "sdio4";
					drive-strength = <0x0a>;
				};

				sd5 {
					pins = "gpio30";
					function = "sdio5";
					drive-strength = <0x0a>;
				};

				sd6 {
					pins = "gpio31";
					function = "sdio6";
					drive-strength = <0x0a>;
				};

				sd7 {
					pins = "gpio32";
					function = "sdio7";
					drive-strength = <0x0a>;
					bias-disable;
				};
			};

			ts_0_pinmux {

				mux_1 {
					pins = "gpio34";
					output-high;
				};

				mux_2 {
					pins = "gpio35";
					input-enable;
					bias-pull-up;
				};
			};
		};

		serial@78af000 {
			compatible = "qcom,msm-uartdm-v1.4\0qcom,msm-uartdm";
			reg = <0x78af000 0x200>;
			interrupts = <0x00 0x6b 0x00>;
			status = "ok";
			clocks = <0x02 0x1a 0x02 0x15>;
			clock-names = "core\0iface";
			pinctrl-0 = <0x48>;
			pinctrl-names = "default";
		};

		serial@78b0000 {
			compatible = "qcom,msm-uartdm-v1.4\0qcom,msm-uartdm";
			reg = <0x78b0000 0x200>;
			interrupts = <0x00 0x6c 0x00>;
			status = "ok";
			clocks = <0x02 0x1b 0x02 0x15>;
			clock-names = "core\0iface";
			pinctrl-0 = <0x49>;
			pinctrl-names = "default";
		};

		qcom,sps {
			compatible = "qcom,msm_sps_4k";
			qcom,device-type = <0x03>;
			qcom,pipe-attr-ee;
		};

		spi@78b5000 {
			compatible = "qcom,spi-qup-v2";
			#address-cells = <0x01>;
			#size-cells = <0x00>;
			reg-names = "spi_physical\0spi_bam_physical";
			reg = <0x78b5000 0x600 0x7884000 0x23000>;
			interrupt-names = "spi_irq\0spi_bam_irq";
			interrupts = <0x00 0x5f 0x00 0x00 0xee 0x00>;
			spi-max-frequency = <0x16e3600>;
			clocks = <0x02 0x17 0x02 0x15>;
			clock-names = "core_clk\0iface_clk";
			qcom,infinite-mode = <0x00>;
			qcom,use-bam;
			qcom,bam-consumer-pipe-index = <0x04>;
			qcom,bam-producer-pipe-index = <0x05>;
			qcom,master-id = <0x00>;
			status = "ok";
			pinctrl-0 = <0x4a>;
			pinctrl-names = "default";

			m25p80@0 {
				#address-cells = <0x01>;
				#size-cells = <0x01>;
				reg = <0x00>;
				compatible = "n25q128a11";
				linux,modalias = "m25p80\0n25q128a11";
				spi-max-frequency = <0x16e3600>;
				use-default-sizes;
			};
		};

		spi@78b6000 {
			compatible = "qcom,spi-qup-v2";
			#address-cells = <0x01>;
			#size-cells = <0x00>;
			reg-names = "spi_physical\0spi_bam_physical";
			reg = <0x78b6000 0x600 0x7884000 0x23000>;
			interrupt-names = "spi_irq\0spi_bam_irq";
			interrupts = <0x00 0x60 0x00 0x00 0xee 0x00>;
			spi-max-frequency = <0x16e3600>;
			clocks = <0x02 0x19 0x02 0x15>;
			clock-names = "core_clk\0iface_clk";
			qcom,infinite-mode = <0x00>;
			qcom,use-bam;
			qcom,bam-consumer-pipe-index = <0x06>;
			qcom,bam-producer-pipe-index = <0x07>;
			qcom,master-id = <0x00>;
			status = "disabled";
		};

		qcom,nand@7980000 {
			compatible = "qcom,msm-nand";
			reg = <0x7980000 0x40000 0x7984000 0x1a000>;
			reg-names = "nand_phys\0bam_phys";
			interrupts = <0x00 0x65 0x00>;
			interrupt-names = "bam_irq";
			qcom,msm-bus,name = "qpic_nand";
			qcom,msm-bus,num-cases = <0x02>;
			qcom,msm-bus,num-paths = <0x01>;
			qcom,msm-bus,vectors-KBps = <0x5b 0x200 0x00 0x00 0x5b 0x200 0x61a80 0xc3500>;
			clock-names = "iface_clk\0core_clk";
			clocks = <0x02 0x2b 0x02 0x2c>;
			status = "ok";
		};

		tcsr@194b000 {
			compatible = "qcom,tcsr";
			reg = <0x194b000 0x100>;
			qcom,usb-hsphy-mode-select = <0xe700e7>;
			status = "ok";
		};

		ess_tcsr@1953000 {
			compatible = "qcom,tcsr";
			reg = <0x1953000 0x1000>;
			qcom,ess-interface-select = <0x00>;
		};

		ssphy@0 {
			compatible = "qca,uni-ssphy";
			reg = <0x9a000 0x800>;
			reg-names = "phy_base";
			resets = <0x02 0x0c>;
			reset-names = "por_rst";
			qca,host = <0x01>;
			qca,emulation = <0x00>;
			status = "ok";
			linux,phandle = <0x4c>;
			phandle = <0x4c>;
		};

		ssphy@1 {
			compatible = "qca,dummy-ssphy";
			status = "ok";
			linux,phandle = <0x4e>;
			phandle = <0x4e>;
		};

		hsphy@a6000 {
			compatible = "qca,baldur-usb3-hsphy";
			reg = <0xa6000 0x40>;
			reg-names = "phy_base";
			resets = <0x02 0x0d 0x02 0x0e>;
			reset-names = "por_rst\0srif_rst";
			qca,host = <0x01>;
			qca,emulation = <0x00>;
			status = "ok";
			linux,phandle = <0x4b>;
			phandle = <0x4b>;
		};

		hsphy@a8000 {
			compatible = "qca,baldur-usb2-hsphy";
			reg = <0xa8000 0x40>;
			reg-names = "phy_base";
			resets = <0x02 0x0f 0x02 0x10>;
			reset-names = "por_rst\0srif_rst";
			qca,host = <0x01>;
			qca,emulation = <0x00>;
			status = "ok";
			linux,phandle = <0x4d>;
			phandle = <0x4d>;
		};

		usb3@8a00000 {
			compatible = "qca,dwc3";
			#address-cells = <0x01>;
			#size-cells = <0x01>;
			ranges;
			reg = <0x8af8800 0x100>;
			reg-names = "qscratch_base";
			clocks = <0x02 0x37 0x02 0x38 0x02 0x39>;
			clock-names = "master\0sleep\0mock_utmi";
			qca,host = <0x01>;
			status = "ok";

			dwc3@8a00000 {
				compatible = "snps,dwc3";
				reg = <0x8a00000 0xf8000>;
				interrupts = <0x00 0x84 0x00>;
				usb-phy = <0x4b 0x4c>;
				phy-names = "usb2-phy\0usb3-phy";
				tx-fifo-resize;
				dr_mode = "host";
				usb2-susphy-quirk;
				usb2-host-discon-quirk;
				usb2-host-discon-phy-misc-reg = <0x24>;
				usb2-host-discon-mask = <0x100>;
			};
		};

		usb2@6000000 {
			compatible = "qca,dwc3";
			#address-cells = <0x01>;
			#size-cells = <0x01>;
			ranges;
			reg = <0x60f8800 0x100>;
			reg-names = "qscratch_base";
			clocks = <0x02 0x34 0x02 0x35 0x02 0x36>;
			clock-names = "master\0sleep\0mock_utmi";
			qca,host = <0x01>;
			status = "ok";

			dwc3@6000000 {
				compatible = "snps,dwc3";
				reg = <0x6000000 0xf8000>;
				interrupts = <0x00 0x88 0x00>;
				usb-phy = <0x4d 0x4e>;
				phy-names = "usb2-phy\0usb3-phy";
				tx-fifo-resize;
				dr_mode = "host";
				usb2-susphy-quirk;
				usb2-host-discon-quirk;
				usb2-host-discon-phy-misc-reg = <0x24>;
				usb2-host-discon-mask = <0x100>;
			};
		};

		rng@0x00022000 {
			compatible = "qcom,prng";
			reg = <0x22000 0x140>;
			clocks = <0x02 0x2a>;
			clock-names = "core";
		};

		i2c@78b7000 {
			compatible = "qcom,i2c-msm-v2";
			#address-cells = <0x01>;
			#size-cells = <0x00>;
			reg-names = "qup_phys_addr\0bam_phys_addr";
			reg = <0x78b7000 0x600 0x7884000 0x23000>;
			interrupt-names = "qup_irq\0bam_irq";
			interrupts = <0x00 0x61 0x00 0x00 0xee 0x00>;
			clocks = <0x02 0x15 0x02 0x16>;
			clock-names = "iface_clk\0core_clk";
			qcom,clk-freq-out = <0x186a0>;
			qcom,clk-freq-in = <0x122ae10>;
			qcom,noise-rjct-scl = <0x00>;
			qcom,noise-rjct-sda = <0x00>;
			qcom,bam-pipe-idx-cons = <0x08>;
			qcom,bam-pipe-idx-prod = <0x09>;
			qcom,master-id = <0x00>;
			status = "ok";
			pinctrl-0 = <0x4f>;
			pinctrl-1 = <0x4f>;
			pinctrl-names = "i2c_active\0i2c_sleep";

			qca_codec@12 {
				compatible = "qca,ipq40xx-codec";
				reg = <0x12>;
				status = "disabled";
			};

			lcd_ts@40 {
				compatible = "qca,gsl1680_ts";
				reg = <0x40>;
				status = "disabled";
			};
		};

		i2c@78b8000 {
			compatible = "qcom,i2c-msm-v2";
			#address-cells = <0x01>;
			#size-cells = <0x00>;
			reg-names = "qup_phys_addr\0bam_phys_addr";
			reg = <0x78b8000 0x600 0x7884000 0x23000>;
			interrupt-names = "qup_irq\0bam_irq";
			interrupts = <0x00 0x62 0x00 0x00 0xee 0x00>;
			clocks = <0x02 0x15 0x02 0x18>;
			clock-names = "iface_clk\0core_clk";
			qcom,clk-freq-out = <0x186a0>;
			qcom,clk-freq-in = <0x122ae10>;
			qcom,noise-rjct-scl = <0x00>;
			qcom,noise-rjct-sda = <0x00>;
			qcom,bam-pipe-idx-cons = <0x0a>;
			qcom,bam-pipe-idx-prod = <0x0b>;
			qcom,master-id = <0x00>;
			status = "disabled";
		};

		qcrypto@8e20000 {
			compatible = "qcom,qcrypto";
			reg = <0x8e20000 0x20000 0x8e04000 0x20000>;
			reg-names = "crypto-base\0crypto-bam-base";
			interrupts = <0x00 0xcf 0x00>;
			qcom,bam-pipe-pair = <0x01>;
			qcom,ce-hw-instance = <0x00>;
			qcom,ce-hw-shared = <0x01>;
			qcom,ce-device = <0x00>;
			qcom,ce-opp-freq = <0x7735940>;
			clocks = <0x02 0x22 0x02 0x21 0x02 0x20>;
			clock-names = "core_clk\0bus_clk\0iface_clk";
			status = "ok";
		};

		qcedev@8e20000 {
			compatible = "qcom,qcedev";
			reg = <0x8e20000 0x20000 0x8e04000 0x20000>;
			reg-names = "crypto-base\0crypto-bam-base";
			interrupts = <0x00 0xcf 0x00>;
			qcom,bam-pipe-pair = <0x01>;
			qcom,ce-hw-instance = <0x00>;
			qcom,ce-hw-shared = <0x01>;
			qcom,ce-device = <0x00>;
			qcom,ce-opp-freq = <0x7735940>;
			clocks = <0x02 0x22 0x02 0x21 0x02 0x20>;
			clock-names = "core_clk\0bus_clk\0iface_clk";
			status = "ok";
		};

		tcsr@1949000 {
			compatible = "qcom,tcsr";
			reg = <0x1949000 0x100>;
			qcom,wifi_glb_cfg = <0x41000000>;
		};

		tcsr@1957000 {
			compatible = "qcom,tcsr";
			reg = <0x1957000 0x100>;
			qcom,wifi_noc_memtype_m0_m2 = <0x2222222>;
		};

		wifi@a000000 {
			compatible = "qca,wifi-ipq40xx";
			reg = <0xa000000 0x200000>;
			core-id = <0x00>;
			resets = <0x02 0x00 0x02 0x01 0x02 0x02 0x02 0x03 0x02 0x04 0x02 0x05>;
			reset-names = "wifi_cpu_init\0wifi_radio_srif\0wifi_radio_warm\0wifi_radio_cold\0wifi_core_warm\0wifi_core_cold";
			clocks = <0x02 0x3a 0x02 0x3b 0x02 0x3c>;
			clock-names = "wifi_wcss_cmd\0wifi_wcss_ref\0wifi_wcss_rtc";
			interrupts = <0x00 0x20 0x01 0x00 0x21 0x01 0x00 0x22 0x01 0x00 0x23 0x01 0x00 0x24 0x01 0x00 0x25 0x01 0x00 0x26 0x01 0x00 0x27 0x01 0x00 0x28 0x01 0x00 0x29 0x01 0x00 0x2a 0x01 0x00 0x2b 0x01 0x00 0x2c 0x01 0x00 0x2d 0x01 0x00 0x2e 0x01 0x00 0x2f 0x01 0x00 0xa8 0x00>;
			interrupt-names = "msi0\0msi1\0msi2\0msi3\0msi4\0msi5\0msi6\0msi7\0msi8\0msi9\0msi10\0msi11\0msi12\0msi13\0msi14\0msi15\0legacy";
			status = "ok";
			qca,msi_addr = <0xb006040>;
			qca,msi_base = <0x40>;
			wifi_led_num = <0x02>;
			wifi_led_source = <0x00>;
		};

		wifi@a800000 {
			compatible = "qca,wifi-ipq40xx";
			reg = <0xa800000 0x200000>;
			core-id = <0x01>;
			resets = <0x02 0x06 0x02 0x07 0x02 0x08 0x02 0x09 0x02 0x0a 0x02 0x0b>;
			reset-names = "wifi_cpu_init\0wifi_radio_srif\0wifi_radio_warm\0wifi_radio_cold\0wifi_core_warm\0wifi_core_cold";
			clocks = <0x02 0x3d 0x02 0x3e 0x02 0x3f>;
			clock-names = "wifi_wcss_cmd\0wifi_wcss_ref\0wifi_wcss_rtc";
			interrupts = <0x00 0x30 0x01 0x00 0x31 0x01 0x00 0x32 0x01 0x00 0x33 0x01 0x00 0x34 0x01 0x00 0x35 0x01 0x00 0x36 0x01 0x00 0x37 0x01 0x00 0x38 0x01 0x00 0x39 0x01 0x00 0x3a 0x01 0x00 0x3b 0x01 0x00 0x3c 0x01 0x00 0x3d 0x01 0x00 0x3e 0x01 0x00 0x3f 0x01 0x00 0xa9 0x00>;
			interrupt-names = "msi0\0msi1\0msi2\0msi3\0msi4\0msi5\0msi6\0msi7\0msi8\0msi9\0msi10\0msi11\0msi12\0msi13\0msi14\0msi15\0legacy";
			status = "ok";
			qca,msi_addr = <0xb006040>;
			qca,msi_base = <0x50>;
			wifi_led_num = <0x01>;
			wifi_led_source = <0x02>;
		};

		edma@c080000 {
			compatible = "qcom,ess-edma";
			reg = <0xc080000 0x8000>;
			qcom,page-mode = <0x00>;
			qcom,rx_head_buf_size = <0x604>;
			qcom,num_gmac = <0x03>;
			qcom,mdio_supported;
			interrupts = <0x00 0x41 0x01 0x00 0x42 0x01 0x00 0x43 0x01 0x00 0x44 0x01 0x00 0x45 0x01 0x00 0x46 0x01 0x00 0x47 0x01 0x00 0x48 0x01 0x00 0x49 0x01 0x00 0x4a 0x01 0x00 0x4b 0x01 0x00 0x4c 0x01 0x00 0x4d 0x01 0x00 0x4e 0x01 0x00 0x4f 0x01 0x00 0x50 0x01 0x00 0xf0 0x01 0x00 0xf1 0x01 0x00 0xf2 0x01 0x00 0xf3 0x01 0x00 0xf4 0x01 0x00 0xf5 0x01 0x00 0xf6 0x01 0x00 0xf7 0x01 0x00 0xf8 0x01 0x00 0xf9 0x01 0x00 0xfa 0x01 0x00 0xfb 0x01 0x00 0xfc 0x01 0x00 0xfd 0x01 0x00 0xfe 0x01 0x00 0xff 0x01>;

			gmac0 {
				local-mac-address = [00 00 00 00 00 00];
				qcom,phy_mdio_addr = <0x09>;
				qcom,poll_required = <0x01>;
				qcom,forced_speed = <0x3e8>;
				qcom,forced_duplex = <0x01>;
				vlan_tag = <0x02 0x04>;
			};

			gmac1 {
				local-mac-address = [00 00 00 00 00 00];
				vlan_tag = <0x01 0x38>;
			};

			gmac2 {
				local-mac-address = [00 00 00 00 00 00];
				qcom,phy_mdio_addr = <0x08>;
				qcom,poll_required = <0x01>;
				qcom,forced_speed = <0x3e8>;
				qcom,forced_duplex = <0x01>;
				vlan_tag = <0x03 0x02>;
			};
		};

		qcom,pcie@80000 {
			compatible = "qcom,msm_pcie";
			cell-index = <0x00>;
			qcom,ctrl-amt = <0x01>;
			reg = <0x80000 0x2000 0x99000 0x800 0x40000000 0xf1d 0x40000f20 0xa8 0x40100000 0x1000 0x40200000 0x100000 0x40300000 0xd00000>;
			reg-names = "parf\0phy\0dm_core\0elbi\0conf\0io\0bars";
			#address-cells = <0x00>;
			interrupt-parent = <0x50>;
			interrupts = <0x00 0x01 0x02 0x03 0x04 0x05 0x06 0x07 0x08 0x09 0x0a 0x0b 0x0c>;
			#interrupt-cells = <0x01>;
			interrupt-map-mask = <0xffffffff>;
			interrupt-map = <0x00 0x01 0x00 0x8d 0x00 0x01 0x01 0x00 0x8e 0x00 0x02 0x01 0x00 0x8f 0x00 0x03 0x01 0x00 0x90 0x00 0x04 0x01 0x00 0x91 0x00 0x05 0x01 0x00 0x92 0x00 0x06 0x01 0x00 0x93 0x00 0x07 0x01 0x00 0x94 0x00 0x08 0x01 0x00 0x95 0x00 0x09 0x01 0x00 0x96 0x00 0x0a 0x01 0x00 0x97 0x00 0x0b 0x01 0x00 0x98 0x00>;
			interrupt-names = "int_msi\0int_a\0int_b\0int_c\0int_d\0int_pls_pme\0int_pme_legacy\0int_pls_err\0int_aer_legacy\0int_pls_link_up\0int_pls_link_down\0int_bridge_flush_n\0int_wake";
			qcom,ep-latency = <0x0a>;
			clocks = <0x02 0x26 0x02 0x27 0x02 0x28>;
			clock-names = "pcie_0_cfg_ahb_clk\0pcie_0_mstr_axi_clk\0pcie_0_slv_axi_clk";
			max-clock-frequency-hz = <0x00 0x00 0x00>;
			resets = <0x02 0x1c 0x02 0x1b 0x02 0x1a 0x02 0x19 0x02 0x18 0x02 0x17 0x02 0x16 0x02 0x15 0x02 0x14 0x02 0x13 0x02 0x12 0x02 0x11>;
			reset-names = "pcie_rst_axi_m_ares\0pcie_rst_axi_s_ares\0pcie_rst_pipe_ares\0pcie_rst_axi_m_vmidmt_ares\0pcie_rst_axi_s_xpu_ares\0pcie_rst_parf_xpu_ares\0pcie_rst_phy_ares\0pcie_rst_axi_m_sticky_ares\0pcie_rst_pipe_sticky_ares\0pcie_rst_pwr_ares\0pcie_rst_ahb_res\0pcie_rst_phy_ahb_ares";
			status = "ok";
			perst-gpio = <0x51 0x26 0x00>;
			wake-gpio = <0x51 0x28 0x00>;
			clkreq-gpio = <0x51 0x27 0x00>;
			linux,phandle = <0x50>;
			phandle = <0x50>;
		};

		pwm {
			compatible = "qca,ipq4019-pwm";
			clocks = <0x02 0x14>;
			clock-names = "core";
			pwm-base-index = <0x00>;
			used-pwm-indices = <0x01 0x01 0x01 0x01>;
			status = "disabled";
		};

		ledc@1937000 {
			compatible = "qca,ledc";
			reg = <0x1937000 0x20070>;
			reg-names = "ledc_base_addr";
			qcom,tcsr_ledc_values = <0x320193 0x14720800 0x20d 0x00 0x00 0xffffffff 0x00 0x07 0x7d0010 0x00 0x10482090 0x3fffdfc>;
			qcom,ledc_blink_indices_cnt = <0x00>;
			qcom,ledc_blink_indices = <0x00>;
			status = "ok";
			pinctrl-0 = <0x52>;
			pinctrl-names = "default";
		};

		pmu {
			compatible = "arm,cortex-a7-pmu";
			interrupts = <0x01 0x07 0xf04>;
		};

		sdhci@7824000 {
			compatible = "qcom,sdhci-msm-v4";
			reg = <0x7824900 0x11c 0x7824000 0x800>;
			interrupts = <0x00 0x7b 0x00 0x00 0x8a 0x00>;
			bus-width = <0x08>;
			clocks = <0x02 0x2e 0x02 0x2d>;
			clock-names = "core\0iface";
			status = "ok";
			pinctrl-0 = <0x53>;
			pinctrl-names = "default";
			vqmmc-supply = <0x54>;
			cd-gpios = <0x51 0x16 0x01>;
			sd-ldo-gpios = <0x51 0x21 0x01>;
		};

		ess-switch@c000000 {
			compatible = "qcom,ess-switch";
			reg = <0xc000000 0x80000>;
			switch_access_mode = "local bus";
			resets = <0x02 0x1d 0x02 0x4e 0x02 0x4f 0x02 0x50 0x02 0x51 0x02 0x52>;
			reset-names = "ess_rst\0ess_mac1_clk_dis\0ess_mac2_clk_dis\0ess_mac3_clk_dis\0ess_mac4_clk_dis\0ess_mac5_clk_dis";
			clocks = <0x02 0x23>;
			clock-names = "ess_clk";
			switch_cpu_bmp = <0x01>;
			switch_lan_bmp = <0x38>;
			switch_wan_bmp = <0x06>;
			slave_s17c_support = <0x01>;
			switch_mac_mode = <0x00>;
			switch_initvlas = <0x7c 0x54>;

			led_source@0 {
				source = <0x01>;
				mode = "normal";
				speed = "all";
				freq = "auto";
			};

			led_source@1 {
				source = <0x04>;
				mode = "normal";
				speed = "all";
				freq = "auto";
			};

			led_source@2 {
				source = <0x07>;
				mode = "normal";
				speed = "all";
				freq = "auto";
			};

			led_source@3 {
				source = <0x0a>;
				mode = "normal";
				speed = "all";
				freq = "auto";
			};

			led_source@4 {
				source = <0x0d>;
				mode = "normal";
				speed = "all";
				freq = "auto";
			};
		};

		ess-psgmii@98000 {
			compatible = "qcom,ess-psgmii";
			reg = <0x98000 0x800>;
			psgmii_access_mode = "local bus";
			resets = <0x02 0x4d>;
			reset-names = "psgmii_rst";
		};

		mdio@90000 {
			#address-cells = <0x01>;
			#size-cells = <0x01>;
			compatible = "qcom,ipq40xx-mdio";
			reg = <0x90000 0x64>;

			ethernet-phy@0 {
				reg = <0x08>;
			};

			ethernet-phy@1 {
				reg = <0x09>;
			};

			ethernet-phy@2 {
				reg = <0x0a>;
			};

			ethernet-phy@3 {
				reg = <0x0b>;
			};

			ethernet-phy@4 {
				reg = <0x0c>;
			};
		};

		qca,scm_restart_reason {
			compatible = "qca,scm_restart_reason";
		};

		cpu_freq_ipq40xx {
			compatible = "qca,ipq40xx_freq";
			clock-latency = <0x186a0>;
			qcom,cpufreq-table = <0xbb80 0x30d40 0x7a120 0xaece0>;
		};

		uart@78b0000 {
			compatible = "qcom,msm-hsuart-v14";
			reg = <0x78b0000 0x200 0x7884000 0x23000>;
			reg-names = "core_mem\0bam_mem";
			interrupt-names = "core_irq\0bam_irq";
			#address-cells = <0x00>;
			interrupt-parent = <0x55>;
			interrupts = <0x00 0x01 0x02>;
			#interrupt-cells = <0x01>;
			interrupt-map-mask = <0xffffffff>;
			interrupt-map = <0x00 0x01 0x00 0x6c 0x00 0x01 0x01 0x00 0xee 0x00>;
			qcom,bam-tx-ep-pipe-index = <0x02>;
			qcom,bam-rx-ep-pipe-index = <0x03>;
			qcom,master-id = <0x56>;
			clocks = <0x02 0x15 0x02 0x1b>;
			clock-names = "iface_clk\0core_clk";
			status = "disabled";
			pinctrl-0 = <0x56>;
			pinctrl-1 = <0x56>;
			pinctrl-names = "default\0sleep";
			linux,phandle = <0x55>;
			phandle = <0x55>;
		};

		regulator@0 {
			compatible = "qcom,regulator-ipq40xx";
			regulator-name = "SD0 VccQ";
			regulator-min-microvolt = <0x1b7740>;
			regulator-max-microvolt = <0x2dc6c0>;
			states = <0x2dc6c0 0x03 0x1b7740 0x01>;
			reg = <0x1948000 0x04>;
			mask = <0x03>;
			linux,phandle = <0x54>;
			phandle = <0x54>;
		};

		gpio_keys {
			compatible = "gpio-keys";

			button@1 {
				label = "wps";
				linux,code = <0x211>;
				gpios = <0x51 0x12 0x01>;
				linux,input-type = <0x01>;
			};
		};

		qcom,msm_qpic@7980000 {
			compatible = "qcom,mdss_qpic";
			reg = <0x7980000 0x24000>;
			reg-names = "qpic_base";
			interrupt-names = "lcdc_irq\0bam_irq";
			interrupts = <0x00 0x6a 0x00 0x00 0x65 0x00>;
			qcom,msm-bus,name = "mdss_qpic";
			qcom,msm-bus,num-cases = <0x02>;
			qcom,msm-bus,num-paths = <0x01>;
			qcom,msm-bus,vectors-KBps = <0x5b 0x200 0x00 0x00 0x5b 0x200 0x61a80 0xc3500>;
			status = "ok";
		};

		qcom,mdss_lcd_qpic_panel {
			compatible = "qcom,mdss-qpic-panel";
			label = "qpic lcd panel";
			qcom,mdss-pan-res = <0x320 0x1e0>;
			qcom,mdss-pan-bpp = <0x12>;
			qcom,refresh_rate = <0x3c>;
			status = "ok";
		};
	};

	reserved-memory {
		#address-cells = <0x01>;
		#size-cells = <0x01>;
		ranges;

		rsvd1@87000000 {
			reg = <0x87000000 0x500000>;
			no-map;
		};

		wifi_dump@87500000 {
			reg = <0x87500000 0x600000>;
			no-map;
		};

		rsvd2@87B00000 {
			reg = <0x87b00000 0x500000>;
			no-map;
		};
	};
};
